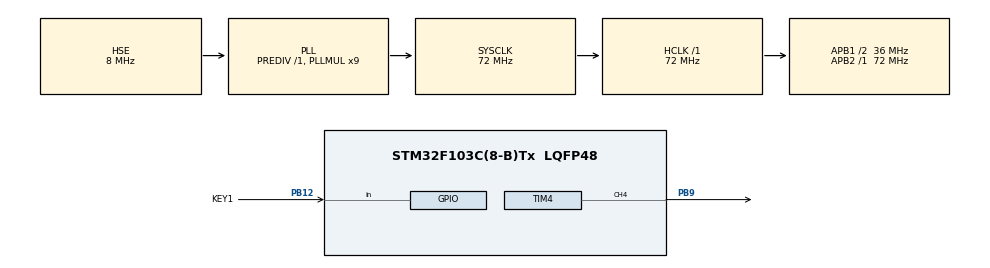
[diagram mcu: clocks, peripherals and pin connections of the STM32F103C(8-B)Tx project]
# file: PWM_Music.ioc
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Mcu.Family=STM32F1
Mcu.Name=STM32F103C(8-B)Tx
Mcu.Package=LQFP48
NVIC.PriorityGroup=NVIC_PRIORITYGROUP_4
PA13.Mode=Serial_Wire
PA13.Signal=SYS_JTMS-SWDIO
PA14.Mode=Serial_Wire
PA14.Signal=SYS_JTCK-SWCLK
PB12.GPIO_Label=KEY1
PB12.Signal=GPIO_Input
PB9.Signal=S_TIM4_CH4
PD0-OSC_IN.Mode=HSE-External-Oscillator
PD0-OSC_IN.Signal=RCC_OSC_IN
PD1-OSC_OUT.Mode=HSE-External-Oscillator
PD1-OSC_OUT.Signal=RCC_OSC_OUT
ProjectManager.HeapSize=0x200
ProjectManager.StackSize=0x400
ProjectManager.TargetToolchain=MDK-ARM V5.32
RCC.AHBFreq_Value=72000000
RCC.APB1CLKDivider=RCC_HCLK_DIV2
RCC.APB1Freq_Value=36000000
RCC.APB1TimFreq_Value=72000000
RCC.APB2Freq_Value=72000000
RCC.APB2TimFreq_Value=72000000
RCC.HCLKFreq_Value=72000000
RCC.PLLMUL=RCC_PLL_MUL9
RCC.PLLSourceVirtual=RCC_PLLSOURCE_HSE
RCC.SYSCLKFreq_VALUE=72000000
RCC.SYSCLKSource=RCC_SYSCLKSOURCE_PLLCLK
RCC.USBFreq_Value=72000000
SH.S_TIM4_CH4.0=TIM4_CH4,PWM Generation4 CH4
TIM4.Channel-PWM\ Generation4\ CH4=TIM_CHANNEL_4
TIM4.Prescaler=72-1
VP_TIM4_VS_ClockSourceINT.Mode=Internal
board=custom

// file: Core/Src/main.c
/* USER CODE BEGIN Header */
/**
  ******************************************************************************
  * @file           : main.c
  * @brief          : Main program body
  ******************************************************************************
  * @attention
  *
  * Copyright (c) 2025 STMicroelectronics.
  * All rights reserved.
  *
  * This software is licensed under terms that can be found in the LICENSE file
  * in the root directory of this software component.
  * If no LICENSE file comes with this software, it is provided AS-IS.
  *
  ******************************************************************************
  */
/* USER CODE END Header */
#include "main.h"

/* USER CODE BEGIN PD */
#define P0 	0	// 休止符频率

#define L1 262  // 低音频率
#define L2 294
#define L3 330
#define L4 349
#define L5 392
#define L6 440
#define L7 494

#define M1 523  // 中音频率
#define M2 587
#define M3 659
#define M4 698
#define M5 784
#define M6 880
#define M7 988

#define H1 1047 // 高音频率
#define H2 1175
#define H3 1319
#define H4 1397
#define H5 1568
#define H6 1760
#define H7 1976

typedef struct
{
    uint16_t frequency;
    float period;
} Bate;
/* USER CODE END PD */

TIM_HandleTypeDef htim4;

/* USER CODE BEGIN PV */
const Bate MoChouXiang[] = {
    // 我被困在了
    {M6, 1}, {M5, 1}, {M3, 1}, {M5, 0.5f}, {M5, 0.5f},
    // 这片混沌 柳暗
    {M6, 0.5f}, {M5, 1}, {M5, 0.5f}, {M3, 0.5f}, {M3, 0.5f}, {M3, 0.5f}, {M3, 0.5f},
    // 花明 一村一村一村
    {M2, 0.5f}, {M3, 0.5f}, {M5, 0.5f}, {M3, 0.5f}, {M2, 0.5f}, {M3, 0.5f}, {M5, 0.5f}, {M3, 0.5f},
    // 一村又一村
    {M2, 0.5f}, {M3, 0.5f}, {M3, 0.5f}, {L7, 0.5f}, {M3, 1}, {M1, 1},
    // 不能理顺我
    {M2, 1}, {M3, 1}, {M2, 1}, {M3, 0.5f}, {M3, 0.5f},
    // 自己的疑问
    {M2, 0.5f}, {M3, 0.5f}, {M2, 0.5f}, {M5, 1.5f}, {M3, 1},
    // 病榻上传来了我微
    {M3, 0.5f}, {M3, 0.5f}, {M3, 0.5f}, {M2, 0.5f}, {M2, 0.5f}, {M2, 0.5f}, {M2, 0.5f}, {M2, 0.5f},
    // 弱的呼吸声，没有啥大能
    {M1, 0.5f}, {M3, 0.5f}, {M1, 0.125f}, {M3, 0.125f}, {M5, 0.25f}, {M5, 0.5f}, {M5, 0.5f}, {M3, 0.5f}, {M2, 0.5f}, {M3, 0.5f},
    // 耐，也无法忍受失
    {M5, 0.5f}, {M3, 0.5f}, {M3, 0.5f}, {M3, 0.5f}, {M2, 0.5f}, {M3, 0.5f}, {M5, 0.5f}, {M3, 0.5f},
    // 败 杀死人的从
    {M1, 0.5f}, {P0, 0.5f}, {P0, 0.5f}, {M5, 0.5f}, {M5, 0.5f}, {M3, 0.5f}, {M2, 0.5f}, {M3, 0.5f},
    // 来不是挫折而是期
    {M5, 0.5f}, {M3, 0.5f}, {M2, 0.5f}, {M3, 0.5f}, {M2, 0.5f}, {M3, 0.5f}, {M5, 0.5f}, {M3, 0.5f},
    // 待 遏制住我发
    {M2, 1}, {P0, 0.5f}, {M5, 0.5f}, {M5, 0.5f}, {M6, 0.5f}, {M3, 0.5f}, {M5, 0.5f},
    // 疯 也没有让我太痛
    {M5, 0.5f}, {M1, 0.5f}, {M1, 0.5f}, {M1, 0.5f}, {M1, 0.5f}, {M5, 0.5f}, {M5, 0.5f}, {M3, 0.5f},
    // 快 噢 我茅塞顿
    {M2, 1}, {P0, 0.5f}, {M3, 0.5f}, {M2, 0.5f}, {M3, 0.5f}, {M2, 0.5f}, {M3, 0.5f},
    // 开 原来是自尊心在作
    {M2, 0.5f}, {M2, 0.5f}, {M2, 0.5f}, {M2, 0.5f}, {M3, 0.5f}, {M3, 0.25f}, {M3, 0.25f}, {M3, 0.5f}, {M2, 0.5f},
    // 怪 漏了一拍 我只能
    {M1, 0.5f}, {M5, 0.5f}, {M5, 0.5f}, {M3, 0.5f}, {M5, 0.5f}, {M5, 0.5f}, {M5, 0.5f}, {M5, 0.5f},
    // 每天都把自己搞得很晕
    {M6, 0.5f}, {M5, 0.25f}, {M5, 0.25f}, {M5, 0.5f}, {M5, 0.25f}, {M5, 0.25f}, {M3, 0.25f}, {M5, 0.25f}, {M3, 0.5f}, {M5, 1},
    // 坏事降临头上也不清醒
    {M6, 0.5f}, {M5, 0.25f}, {M5, 0.25f}, {M5, 0.25f}, {M5, 0.25f}, {M5, 0.5f}, {M3, 0.25f}, {M5, 0.25f}, {M5, 0.5f}, {M3, 0.5f}, {M3, 0.5f},
    // 可笼罩在我头顶上的乌云
    {M2, 0.25f}, {M2, 0.25f}, {M2, 0.25f}, {M2, 0.25f}, {M2, 0.25f}, {M1, 0.25f}, {M1, 0.5f}, {M5, 0.25f}, {M5, 0.25f}, {M5, 0.5f}, {M5, 1},
    // 紧跟着逃不出她的手心
    {M2, 0.25f}, {M2, 0.25f}, {M2, 0.5f}, {M2, 0.25f}, {M1, 0.25f}, {M1, 0.5f}, {M5, 0.25f}, {M5, 0.25f}, {M3, 0.5f}, {M5, 1},
    // 呀 我的愁绪千
    {M1, 1}, {P0, 0.5f}, {M5, 0.5f}, {M3, 0.5f}, {M3, 0.5f}, {M3, 0.5f}, {M2, 0.5f},
    // 丝万缕挥之不去
    {M1, 0.5f}, {M1, 0.5f}, {M1, 0.5f}, {M5, 0.5f}, {M3, 0.5f}, {M3, 0.5f}, {M2, 0.25f}, {M3, 0.25f}, {M2, 0.5f},
    // 闭上眼眼眶里下了场雨
    {M2, 0.25f}, {M2, 0.25f}, {M2, 0.5f}, {M2, 0.5f}, {M3, 0.25f}, {M2, 0.25f}, {M2, 0.25f}, {M2, 0.25f}, {M3, 0.5f}, {M2, 1},
    // 坠入了梦乡也弄湿了枕巾
    {M5, 0.5f}, {M5, 0.25f}, {M5, 0.25f}, {M5, 0.5f}, {M5, 0.25f}, {M5, 0.25f}, {M5, 0.25f}, {M6, 0.25f}, {M3, 0.5f}, {M5, 1},
    // 梦把我拽到个好地方 摇
    {M6, 0.5f}, {M5, 0.25f}, {M5, 0.25f}, {M5, 0.5f}, {M3, 0.25f}, {M3, 0.25f}, {M3, 0.5f}, {M5, 0.5f}, {M5, 0.5f}, {M5, 0.5f},
    // 摇晃晃到莫愁乡
    {M6, 0.5f}, {M5, 0.5f}, {M5, 0.5f}, {M3, 0.5f}, {M3, 0.5f}, {M5, 0.5f}, {M5, 1},
    // 炊烟漫过青瓦黛砖
    {M6, 0.5f}, {M5, 0.5f}, {M5, 0.5f}, {M3, 0.5f}, {M3, 0.5f}, {M5, 0.5f}, {M5, 0.5f}, {M5, 0.5f}, {M1, 0.5f},
    // 脚印伴随着微光 这
    {M1, 0.5f}, {M1, 0.5f}, {M1, 0.5f}, {M5, 0.5f}, {M3, 0.5f}, {M3, 0.5f}, {M3, 0.5f}, {M2, 0.5f},
    // 伤 不痛不痒 她
    {M1, 1.5f}, {M5, 0.5f}, {M3, 0.5f}, {M3, 0.5f}, {M3, 0.5f}, {M2, 0.5f},
    // 讲 你在说谎 都是
    {M1, 1}, {P0, 0.5f}, {M5, 0.5f}, {M3, 0.5f}, {M3, 0.5f}, {M3, 0.5f}, {M1, 0.25f}, {M1, 0.25f},
    // 装的坚强 你眼里
    {M3, 0.5f}, {M2, 1}, {M3, 0.5f}, {M2, 0.5f}, {M1, 0.5f}, {M1, 0.5f}, {M1, 0.5f},
    // 带着泪光 我
    {M3, 0.5f}, {M2, 1}, {M3, 0.5f}, {M2, 1.5f}, {M1, 0.5f},
    // 诉愁肠向莫愁乡 把
    {M6, 0.5f}, {M5, 0.5f}, {M5, 0.5f}, {M3, 0.5f}, {M3, 0.5f}, {M5, 0.5f}, {M5, 0.5f}, {M5, 0.5f},
    // 叹息吹成地上霜
    {M6, 0.5f}, {M5, 0.5f}, {M5, 0.5f}, {M3, 0.5f}, {M3, 0.5f}, {M5, 0.5f}, {M5, 1},
    // 明明快崩溃了 却还
    {M6, 0.5f}, {M5, 0.5f}, {M5, 0.5f}, {M3, 0.5f}, {M5, 0.5f}, {M3, 0.5f}, {M1, 0.5f}, {M1, 0.5f},
    // 要乔装无关痛痒 墙
    {M1, 0.5f}, {M1, 0.5f}, {M1, 0.5f}, {M5, 0.5f}, {M3, 0.5f}, {M3, 0.5f}, {M3, 0.5f}, {M2, 0.5f},
    // 边拨浪鼓叮当响 往
    {M1, 0.5f}, {M1, 0.5f}, {M1, 0.5f}, {M5, 0.5f}, {M3, 0.5f}, {M3, 0.5f}, {M3, 0.5f}, {M2, 0.5f},
    // 我手心上放块儿糖
    {M1, 0.5f}, {M1, 0.5f}, {M1, 0.5f}, {M5, 0.5f}, {M3, 0.5f}, {M3, 0.5f}, {M2, 0.5f}, {M3, 0.5f},
    // 娃儿莫慌 姥姥
    {M3, 0.5f}, {M2, 1}, {M3, 0.5f}, {M2, 1}, {M1, 0.5f}, {M1, 0.5f},
    // 在边上 放声
    {M3, 0.5f}, {M2, 1}, {M3, 0.5f}, {M2, 1}, {M1, 0.5f}, {M1, 0.5f},
    // 大哭吧 这里没人
    {M5, 0.5f}, {P0, 0.5f}, {M3, 0.5f}, {M3, 0.5f}, {M2, 0.5f}, {M3, 0.5f}, {M2, 0.5f}, {M3, 0.5f},
    // 会笑话你
    {M3, 0.5f}, {M2, 1}, {M1, 0.5f}, {M5, 0.5f}, {M3, 0.5f}, {M3, 1},
    // 人生大事莫过生死
    {M5, 0.5f}, {M5, 0.5f}, {M6, 0.5f}, {M3, 0.5f}, {M3, 0.5f}, {M5, 0.5f}, {M5, 0.5f}, {M3, 0.5f},
    // 其他都不要紧
    {M5, 0.5f}, {M5, 0.5f}, {M5, 0.5f}, {M3, 0.5f}, {M5, 0.5f}, {M3, 0.5f}, {M1, 1},
    // 现实太要命了 让我
    {M1, 0.5f}, {M3, 0.5f}, {M3, 0.5f}, {M2, 0.5f}, {M3, 0.5f}, {M1, 0.5f}, {M1, 0.5f}, {M1, 0.5f},
    // 时刻想要逃离
    {M1, 0.5f}, {M3, 0.5f}, {M3, 0.5f}, {M2, 0.5f}, {M3, 1}, {M2, 0.5f}, {M3, 0.5f},
    // 可是 可是 转眼
    {M2, 0.5f}, {M2, 0.5f}, {M1, 0.5f}, {M2, 1}, {P0, 0.5f}, {M2, 0.5f}, {M2, 0.5f},
    // 间被闹钟叫醒
    {M1, 0.5f}, {M2, 0.5f}, {M3, 0.5f}, {M2, 0.5f}, {M3, 1}, {M1, 1},
    // 累了就出门溜达溜达
    {M6, 0.5f}, {M5, 0.25f}, {M5, 0.25f}, {M5, 0.5f}, {M5, 0.5f}, {M3, 0.5f}, {M5, 0.5f}, {M3, 0.5f}, {M5, 0.5f},
    // 放心吧兜里够花够花
    {M6, 0.5f}, {M5, 0.25f}, {M5, 0.25f}, {M5, 0.25f}, {M5, 0.25f}, {M5, 0.5f}, {M3, 0.5f}, {M5, 0.5f}, {M3, 0.5f}, {M5, 0.5f},
    // 我骗她是国企 我实际是牛马
    {M1, 0.25f}, {M1, 0.25f}, {M1, 0.25f}, {M1, 0.25f}, {M1, 0.25f}, {M1, 0.5f}, {M5, 0.25f}, {M5, 0.25f}, {M3, 0.25f}, {M3, 0.5f}, {M3, 0.25f}, {M2, 0.5f}, {M3, 0.5f},
    // 早九晚八五天年假
    {M1, 0.5f}, {M1, 0.5f}, {M1, 0.5f}, {M5, 0.5f}, {M2, 0.5f}, {M3, 0.5f}, {M2, 0.5f}, {M3, 0.5f},
    // 幺儿你在那边缺啥少啥
    {M6, 0.5f}, {M5, 0.25f}, {M5, 0.25f}, {M5, 0.25f}, {M5, 0.25f}, {M5, 0.5f}, {M3, 0.5f}, {M5, 0.5f}, {M3, 0.5f}, {M5, 0.5f},
    // 有事没事都打个电话
    {M1, 0.5f}, {M1, 0.5f}, {M1, 0.5f}, {M3, 0.25f}, {M3, 0.25f}, {M3, 0.5f}, {M3, 0.5f}, {M2, 0.5f}, {M3, 0.5f},
    // 幺儿你到底啥时候回家
    {M2, 0.25f}, {M2, 0.25f}, {M2, 0.5f}, {M2, 0.5f}, {M2, 0.5f}, {M2, 0.25f}, {M3, 0.25f}, {M3, 0.5f}, {M3, 0.5f}, {M2, 0.5f},
    // 姥姥种的石榴开花了
    {M2, 0.5f}, {M2, 0.5f}, {M2, 0.5f}, {M2, 0.5f}, {M1, 0.25f}, {M1, 0.25f}, {M3, 0.5f}, {M3, 0.5f}, {M1, 0.5f},
    // 几度梦回莫愁乡 回
    {M6, 0.5f}, {M5, 0.5f}, {M5, 0.5f}, {M3, 0.5f}, {M3, 0.5f}, {M5, 0.5f}, {M5, 0.5f}, {M5, 0.5f},
    // 回梦的都不重样
    {M6, 0.5f}, {M5, 0.5f}, {M5, 0.5f}, {M3, 0.5f}, {M3, 0.5f}, {M5, 0.5f}, {M5, 1},
    // 纸飞机掠过操场后
    {M6, 0.5f}, {M5, 0.5f}, {M5, 0.5f}, {M3, 0.5f}, {M3, 0.5f}, {M3, 0.5f}, {M1, 0.5f}, {M3, 0.5f},
    // 铁了心的要流浪
    {M1, 0.5f}, {M1, 0.5f}, {M1, 0.5f}, {M5, 0.5f}, {M5, 0.5f}, {M3, 0.5f}, {M2, 0.5f}, {M3, 0.5f},
    // 哪管前路几多长
    {M1, 0.5f}, {M1, 0.5f}, {M1, 0.5f}, {M5, 0.5f}, {M5, 0.5f}, {M3, 0.5f}, {M2, 0.5f}, {M3, 0.5f},
    // 偏信远方有朝阳
    {M1, 0.5f}, {M1, 0.5f}, {M1, 0.5f}, {M5, 0.5f}, {M5, 0.5f}, {M3, 0.5f}, {M2, 0.5f}, {M3, 0.5f},
    // 却输岁月半柱香
    {M3, 0.5f}, {M2, 0.5f}, {M2, 0.5f}, {M3, 0.5f}, {M2, 0.5f}, {M3, 0.5f}, {M2, 1},
    // 人走茶凉
    {M3, 0.5f}, {M2, 1}, {M3, 0.5f}, {M2, 1}, {M1, 1},
    // 几度梦回莫愁乡 旧
    {M6, 0.5f}, {M5, 0.5f}, {M5, 0.5f}, {M3, 0.5f}, {M3, 0.5f}, {M5, 0.5f}, {M5, 0.5f}, {M5, 0.5f},
    // 木船飘向芦苇荡
    {M6, 0.5f}, {M5, 0.5f}, {M5, 0.5f}, {M3, 0.5f}, {M3, 0.5f}, {M5, 0.5f}, {M5, 1},
    // 载着未寄出的信 还
    {M6, 0.5f}, {M5, 0.5f}, {M5, 0.5f}, {M3, 0.5f}, {M3, 0.5f}, {M3, 0.5f}, {M3, 0.5f}, {M1, 0.5f},
    //有糖纸染上的香
    {M1, 0.5f}, {M1, 0.5f}, {M1, 0.5f}, {M5, 0.5f}, {M5, 0.5f}, {M3, 0.5f}, {M2, 0.5f}, {M3, 0.5f},
    // 摇 摇摇晃晃
    {M1, 1}, {P0, 0.5f}, {M5, 0.5f}, {M5, 0.5f}, {M3, 0.5f}, {M2, 0.5f}, {M3, 0.5f},
    // 飘 飘飘荡荡
    {M1, 1}, {P0, 0.5f}, {M5, 0.5f}, {M5, 0.5f}, {M3, 0.5f}, {M2, 0.5f}, {M3, 0.5f},
    // 娃儿抬头望
    {M3, 0.5f}, {M2, 0.5f}, {M2, 0.5f}, {M3, 0.5f}, {M3, 0.5f}, {M2, 1.5f},
    // 姥姥在天上
    {M1, 0.5f}, {M3, 0.5f}, {M2, 0.5f}, {M3, 0.5f}, {M2, 1}, {M1, 1},
};

/* USER CODE END PV */

void SystemClock_Config(void);
static void MX_GPIO_Init(void);
static void MX_TIM4_Init(void);

/* USER CODE BEGIN 0 */
/**
 * 计算定时器计数频率
 */
uint32_t TIM_GetCounterFreq(TIM_HandleTypeDef *htim) {
    uint32_t timer_clock;
    // 高级定时器是APB2
    if (htim->Instance == TIM1) {
        timer_clock = HAL_RCC_GetPCLK2Freq();
        // 如果APB分频不为1，定时器时钟会翻倍
        if (HAL_RCC_GetPCLK2Freq() != (HAL_RCC_GetHCLKFreq() / 1)) {
            timer_clock *= 2;
        }
    } else {
    	// 其他定时器是APB1
        timer_clock = HAL_RCC_GetPCLK1Freq();
        // 如果APB分频不为1，定时器时钟会翻倍
        if (HAL_RCC_GetPCLK1Freq() != (HAL_RCC_GetHCLKFreq() / 1)) {
            timer_clock *= 2;
        }
    }

    uint32_t prescaler = htim->Instance->PSC;
    return timer_clock / (prescaler + 1);
}
/* USER CODE END 0 */

int main(void)
{

  /* MCU Configuration--------------------------------------------------------*/

  /* Reset of all peripherals, Initializes the Flash interface and the Systick. */
  HAL_Init();

  /* Configure the system clock */
  SystemClock_Config();

  /* Initialize all configured peripherals */
  MX_GPIO_Init();
  MX_TIM4_Init();
  /* USER CODE BEGIN 2 */
 // 开始PWM输出
  HAL_TIM_PWM_Start(&htim4, TIM_CHANNEL_4);
  // TIM4的计数频率
  uint32_t timFrequency = TIM_GetCounterFreq(&htim4);
  // 播放状态
  uint8_t playState = 0;
  // 播放进度
  uint32_t playIndex = 0;
  // 节拍速度(每分钟多少拍)
  uint8_t bpm = 132;
  // 每拍的持续时间
  float noteDuration = 1000 * 60 / bpm;
  /* USER CODE END 2 */

  /* Infinite loop */
  /* USER CODE BEGIN WHILE */
  while (1)
  {
		// 按键检测，切换播放与暂停
	  if (HAL_GPIO_ReadPin(KEY1_GPIO_Port, KEY1_Pin) == GPIO_PIN_RESET){
		  HAL_Delay(10);
		  if (HAL_GPIO_ReadPin(KEY1_GPIO_Port, KEY1_Pin) == GPIO_PIN_RESET){
			  playState = !playState;
			  while(HAL_GPIO_ReadPin(KEY1_GPIO_Port, KEY1_Pin) == GPIO_PIN_RESET);
		  }
	  }
	  // 播放
	  if (playState){
		  const Bate bate = MoChouXiang[playIndex];
		  if (bate.frequency == P0) {
			  // 休止符
			  __HAL_TIM_SET_COMPARE(&htim4, TIM_CHANNEL_4, 0);
		  } else {
			  // 将频率转换为计数值, 设置到自动重装载寄存器
			  uint32_t arr = timFrequency / bate.frequency;
			  __HAL_TIM_SET_AUTORELOAD(&htim4,arr);
			  // 设置占空比为20%
			  __HAL_TIM_SET_COMPARE(&htim4, TIM_CHANNEL_4, arr / 5); // 20%占空比
			  // 从0开始计数 重置PWM波形
			  __HAL_TIM_SetCounter(&htim4, 0);
		  }
		  // 延时该音符的持续时间 (5ms的空白以区分连续两个相同的音符)
		  HAL_Delay((uint32_t) (bate.period * noteDuration) - 5);
		  __HAL_TIM_SET_COMPARE(&htim4, TIM_CHANNEL_4, 0);
		  HAL_Delay(5);

		  // 下一个音符
		  playIndex++;
		  // 播放结束
		  if (playIndex >= sizeof(MoChouXiang)){
			  playState = 0;
			  playIndex = 0;
		  }
	  }else{
		  __HAL_TIM_SET_COMPARE(&htim4, TIM_CHANNEL_4, 0);
	  }

    /* USER CODE END WHILE */

  }
}

void SystemClock_Config(void)
{
  RCC_OscInitTypeDef RCC_OscInitStruct = {0};
  RCC_ClkInitTypeDef RCC_ClkInitStruct = {0};

  /** Initializes the RCC Oscillators according to the specified parameters
  * in the RCC_OscInitTypeDef structure.
  */
  RCC_OscInitStruct.OscillatorType = RCC_OSCILLATORTYPE_HSE;
  RCC_OscInitStruct.HSEState = RCC_HSE_ON;
  RCC_OscInitStruct.HSEPredivValue = RCC_HSE_PREDIV_DIV1;
  RCC_OscInitStruct.HSIState = RCC_HSI_ON;
  RCC_OscInitStruct.PLL.PLLState = RCC_PLL_ON;
  RCC_OscInitStruct.PLL.PLLSource = RCC_PLLSOURCE_HSE;
  RCC_OscInitStruct.PLL.PLLMUL = RCC_PLL_MUL9;
  if (HAL_RCC_OscConfig(&RCC_OscInitStruct) != HAL_OK)
  {
    Error_Handler();
  }

  /** Initializes the CPU, AHB and APB buses clocks
  */
  RCC_ClkInitStruct.ClockType = RCC_CLOCKTYPE_HCLK|RCC_CLOCKTYPE_SYSCLK
                              |RCC_CLOCKTYPE_PCLK1|RCC_CLOCKTYPE_PCLK2;
  RCC_ClkInitStruct.SYSCLKSource = RCC_SYSCLKSOURCE_PLLCLK;
  RCC_ClkInitStruct.AHBCLKDivider = RCC_SYSCLK_DIV1;
  RCC_ClkInitStruct.APB1CLKDivider = RCC_HCLK_DIV2;
  RCC_ClkInitStruct.APB2CLKDivider = RCC_HCLK_DIV1;

  if (HAL_RCC_ClockConfig(&RCC_ClkInitStruct, FLASH_LATENCY_2) != HAL_OK)
  {
    Error_Handler();
  }
}

static void MX_TIM4_Init(void)
{

  TIM_ClockConfigTypeDef sClockSourceConfig = {0};
  TIM_MasterConfigTypeDef sMasterConfig = {0};
  TIM_OC_InitTypeDef sConfigOC = {0};

  htim4.Instance = TIM4;
  htim4.Init.Prescaler = 72-1;
  htim4.Init.CounterMode = TIM_COUNTERMODE_UP;
  htim4.Init.Period = 65535;
  htim4.Init.ClockDivision = TIM_CLOCKDIVISION_DIV1;
  htim4.Init.AutoReloadPreload = TIM_AUTORELOAD_PRELOAD_DISABLE;
  if (HAL_TIM_Base_Init(&htim4) != HAL_OK)
  {
    Error_Handler();
  }
  sClockSourceConfig.ClockSource = TIM_CLOCKSOURCE_INTERNAL;
  if (HAL_TIM_ConfigClockSource(&htim4, &sClockSourceConfig) != HAL_OK)
  {
    Error_Handler();
  }
  if (HAL_TIM_PWM_Init(&htim4) != HAL_OK)
  {
    Error_Handler();
  }
  sMasterConfig.MasterOutputTrigger = TIM_TRGO_RESET;
  sMasterConfig.MasterSlaveMode = TIM_MASTERSLAVEMODE_DISABLE;
  if (HAL_TIMEx_MasterConfigSynchronization(&htim4, &sMasterConfig) != HAL_OK)
  {
    Error_Handler();
  }
  sConfigOC.OCMode = TIM_OCMODE_PWM1;
  sConfigOC.Pulse = 0;
  sConfigOC.OCPolarity = TIM_OCPOLARITY_HIGH;
  sConfigOC.OCFastMode = TIM_OCFAST_DISABLE;
  if (HAL_TIM_PWM_ConfigChannel(&htim4, &sConfigOC, TIM_CHANNEL_4) != HAL_OK)
  {
    Error_Handler();
  }
  HAL_TIM_MspPostInit(&htim4);

}

static void MX_GPIO_Init(void)
{
  GPIO_InitTypeDef GPIO_InitStruct = {0};

  /* GPIO Ports Clock Enable */
  __HAL_RCC_GPIOD_CLK_ENABLE();
  __HAL_RCC_GPIOB_CLK_ENABLE();
  __HAL_RCC_GPIOA_CLK_ENABLE();

  /*Configure GPIO pin : KEY1_Pin */
  GPIO_InitStruct.Pin = KEY1_Pin;
  GPIO_InitStruct.Mode = GPIO_MODE_INPUT;
  GPIO_InitStruct.Pull = GPIO_NOPULL;
  HAL_GPIO_Init(KEY1_GPIO_Port, &GPIO_InitStruct);

}

void Error_Handler(void)
{
  __disable_irq();
  while (1)
  {
  }
}
